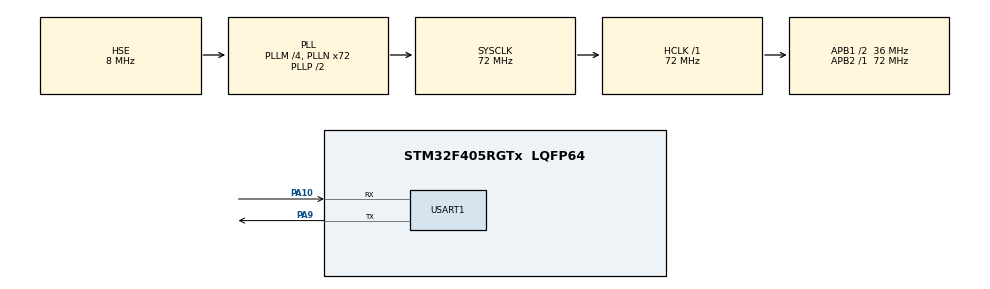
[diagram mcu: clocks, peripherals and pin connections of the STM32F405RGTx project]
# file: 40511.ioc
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Mcu.Family=STM32F4
Mcu.Name=STM32F405RGTx
Mcu.Package=LQFP64
NVIC.PriorityGroup=NVIC_PRIORITYGROUP_4
NVIC.TIM4_IRQn=true\:0\:0\:false\:false\:true
NVIC.USART1_IRQn=true\:0\:0\:false\:false\:true
PA10.Mode=Asynchronous
PA10.Signal=USART1_RX
PA9.Mode=Asynchronous
PA9.Signal=USART1_TX
PH0-OSC_IN.Mode=HSE-External-Oscillator
PH0-OSC_IN.Signal=RCC_OSC_IN
PH1-OSC_OUT.Mode=HSE-External-Oscillator
PH1-OSC_OUT.Signal=RCC_OSC_OUT
ProjectManager.HeapSize=0x2000
ProjectManager.StackSize=0x4000
ProjectManager.TargetToolchain=EWARM
RCC.48MHZClocksFreq_Value=36000000
RCC.AHBFreq_Value=72000000
RCC.APB1CLKDivider=RCC_HCLK_DIV2
RCC.APB1Freq_Value=36000000
RCC.APB1TimFreq_Value=72000000
RCC.APB2Freq_Value=72000000
RCC.APB2TimFreq_Value=72000000
RCC.CortexFreq_Value=72000000
RCC.HCLKFreq_Value=72000000
RCC.HSE_VALUE=8000000
RCC.HSI_VALUE=16000000
RCC.LSE_VALUE=32768
RCC.PLLM=4
RCC.PLLN=72
RCC.PLLSourceVirtual=RCC_PLLSOURCE_HSE
RCC.SYSCLKFreq_VALUE=72000000
RCC.SYSCLKSource=RCC_SYSCLKSOURCE_PLLCLK
RCC.VCOOutputFreq_Value=144000000
TIM4.CounterMode=TIM_COUNTERMODE_UP
TIM4.Period=50
TIM4.Prescaler=35
VP_TIM4_VS_ClockSourceINT.Mode=Internal
board=40511

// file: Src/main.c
/**
  ******************************************************************************
  * File Name          : main.c
  * Description        : Main program body
  ******************************************************************************
  *
  * COPYRIGHT(c) 2016 STMicroelectronics
  *
  * Redistribution and use in source and binary forms, with or without modification,
  * are permitted provided that the following conditions are met:
  *   1. Redistributions of source code must retain the above copyright notice,
  *      this list of conditions and the following disclaimer.
  *   2. Redistributions in binary form must reproduce the above copyright notice,
  *      this list of conditions and the following disclaimer in the documentation
  *      and/or other materials provided with the distribution.
  *   3. Neither the name of STMicroelectronics nor the names of its contributors
  *      may be used to endorse or promote products derived from this software
  *      without specific prior written permission.
  *
  * THIS SOFTWARE IS PROVIDED BY THE COPYRIGHT HOLDERS AND CONTRIBUTORS "AS IS"
  * AND ANY EXPRESS OR IMPLIED WARRANTIES, INCLUDING, BUT NOT LIMITED TO, THE
  * IMPLIED WARRANTIES OF MERCHANTABILITY AND FITNESS FOR A PARTICULAR PURPOSE ARE
  * DISCLAIMED. IN NO EVENT SHALL THE COPYRIGHT HOLDER OR CONTRIBUTORS BE LIABLE
  * FOR ANY DIRECT, INDIRECT, INCIDENTAL, SPECIAL, EXEMPLARY, OR CONSEQUENTIAL
  * DAMAGES (INCLUDING, BUT NOT LIMITED TO, PROCUREMENT OF SUBSTITUTE GOODS OR
  * SERVICES; LOSS OF USE, DATA, OR PROFITS; OR BUSINESS INTERRUPTION) HOWEVER
  * CAUSED AND ON ANY THEORY OF LIABILITY, WHETHER IN CONTRACT, STRICT LIABILITY,
  * OR TORT (INCLUDING NEGLIGENCE OR OTHERWISE) ARISING IN ANY WAY OUT OF THE USE
  * OF THIS SOFTWARE, EVEN IF ADVISED OF THE POSSIBILITY OF SUCH DAMAGE.
  *
  ******************************************************************************
  */
#include "main.h"
#include "stm32f4xx_hal.h"
#include "tim.h"
#include "usart.h"
#include "gpio.h"

/* USER CODE BEGIN Includes */
#include "mb.h"
#include "mbport.h"
#include "mbutils.h"
/* USER CODE END Includes */

/* USER CODE BEGIN PV */

/* Private variables ---------------------------------------------------------*/
#define REG_INPUT_START 0001
#define REG_INPUT_NREGS 100
#define REG_HOLDING_START 0001
#define REG_HOLDING_NREGS 100
#define REG_COILS_START     0001
#define REG_COILS_SIZE      16
#define REG_DISC_START     0001
#define REG_DISC_SIZE      16

/* ----------------------- Static variables ---------------------------------*/
static USHORT usRegInputStart = REG_INPUT_START;
static USHORT usRegInputBuf[REG_INPUT_NREGS];
static USHORT usRegHoldingStart = REG_HOLDING_START;
static USHORT usRegHoldingBuf[REG_HOLDING_NREGS];
static UCHAR ucRegCoilsBuf[REG_COILS_SIZE / 8];
static UCHAR ucRegDiscBuf[REG_DISC_SIZE / 8] =
  { 0, 0 };
/* USER CODE END PV */

void SystemClock_Config(void);
void Error_Handler(void);

/* USER CODE BEGIN PFP */

/* Private function prototypes -----------------------------------------------*/

/* USER CODE END PFP */

/* USER CODE BEGIN 0 */
//uint8_t i=10;
/* USER CODE END 0 */

int main(void)
{

  /* USER CODE BEGIN 1 */
   usRegHoldingBuf[0]=88;
   usRegHoldingBuf[2]=88;
   usRegHoldingBuf[1]=88;
   usRegHoldingBuf[3]=88;
    usRegInputBuf[1]=88;
  /* USER CODE END 1 */

  /* MCU Configuration----------------------------------------------------------*/

  /* Reset of all peripherals, Initializes the Flash interface and the Systick. */
  HAL_Init();

  /* Configure the system clock */
  SystemClock_Config();

  /* Initialize all configured peripherals */
  MX_GPIO_Init();
  MX_USART1_UART_Init();
  MX_TIM4_Init();

  /* USER CODE BEGIN 2 */
  eMBErrorCode eStatus;
  eStatus=eMBInit(MB_RTU, 0x01, 0, 9600, MB_PAR_NONE);
  eStatus=eMBEnable();
  /* USER CODE END 2 */

  /* Infinite loop */
  while (1)
  {

  /* USER CODE BEGIN 3 */
   //HAL_UART_Transmit(&huart1,&i,1,10);
   //HAL_Delay(100);
    ( void )eMBPoll();
  }
  /* USER CODE END 3 */

}

/** System Clock Configuration
*/
void SystemClock_Config(void)
{

  RCC_OscInitTypeDef RCC_OscInitStruct;
  RCC_ClkInitTypeDef RCC_ClkInitStruct;

    /**Configure the main internal regulator output voltage
    */
  __HAL_RCC_PWR_CLK_ENABLE();

  __HAL_PWR_VOLTAGESCALING_CONFIG(PWR_REGULATOR_VOLTAGE_SCALE1);

    /**Initializes the CPU, AHB and APB busses clocks
    */
  RCC_OscInitStruct.OscillatorType = RCC_OSCILLATORTYPE_HSE;
  RCC_OscInitStruct.HSEState = RCC_HSE_ON;
  RCC_OscInitStruct.PLL.PLLState = RCC_PLL_ON;
  RCC_OscInitStruct.PLL.PLLSource = RCC_PLLSOURCE_HSE;
  RCC_OscInitStruct.PLL.PLLM = 4;
  RCC_OscInitStruct.PLL.PLLN = 72;
  RCC_OscInitStruct.PLL.PLLP = RCC_PLLP_DIV2;
  RCC_OscInitStruct.PLL.PLLQ = 4;
  if (HAL_RCC_OscConfig(&RCC_OscInitStruct) != HAL_OK)
  {
    Error_Handler();
  }

    /**Initializes the CPU, AHB and APB busses clocks
    */
  RCC_ClkInitStruct.ClockType = RCC_CLOCKTYPE_HCLK|RCC_CLOCKTYPE_SYSCLK
                              |RCC_CLOCKTYPE_PCLK1|RCC_CLOCKTYPE_PCLK2;
  RCC_ClkInitStruct.SYSCLKSource = RCC_SYSCLKSOURCE_PLLCLK;
  RCC_ClkInitStruct.AHBCLKDivider = RCC_SYSCLK_DIV1;
  RCC_ClkInitStruct.APB1CLKDivider = RCC_HCLK_DIV2;
  RCC_ClkInitStruct.APB2CLKDivider = RCC_HCLK_DIV1;

  if (HAL_RCC_ClockConfig(&RCC_ClkInitStruct, FLASH_LATENCY_2) != HAL_OK)
  {
    Error_Handler();
  }

    /**Configure the Systick interrupt time
    */
  HAL_SYSTICK_Config(HAL_RCC_GetHCLKFreq()/1000);

    /**Configure the Systick
    */
  HAL_SYSTICK_CLKSourceConfig(SYSTICK_CLKSOURCE_HCLK);

  /* SysTick_IRQn interrupt configuration */
  HAL_NVIC_SetPriority(SysTick_IRQn, 0, 0);
}

/* USER CODE BEGIN 4 */
eMBErrorCode eMBRegInputCB(UCHAR * pucRegBuffer, USHORT usAddress, USHORT usNRegs)
{
  eMBErrorCode eStatus = MB_ENOERR;
  int iRegIndex;
  //printf("%d\n", usAddress);
  if ((usAddress >= REG_INPUT_START)
      && (usAddress + usNRegs <= REG_INPUT_START + REG_INPUT_NREGS))
    {
      iRegIndex = (int) (usAddress - usRegInputStart);
      while (usNRegs > 0)
        {
          *pucRegBuffer++ = (unsigned char) (usRegInputBuf[iRegIndex] >> 8);
          *pucRegBuffer++ = (unsigned char) (usRegInputBuf[iRegIndex] & 0xFF);
          iRegIndex++;
          usNRegs--;
        }
    }
  else
    {
      eStatus = MB_ENOREG;
    }

  return eStatus;
}

eMBErrorCode eMBRegHoldingCB(UCHAR * pucRegBuffer, USHORT usAddress, USHORT usNRegs, eMBRegisterMode eMode)
{
  eMBErrorCode eStatus;
  int iRegIndex;
  if ((usAddress >= REG_HOLDING_START)
      && (usAddress + usNRegs <= REG_HOLDING_START + REG_HOLDING_NREGS))
    {
      iRegIndex = (int) (usAddress - usRegHoldingStart);
      switch (eMode)
        {
      case MB_REG_READ:
        while (usNRegs > 0)
          {
            *pucRegBuffer++ = (UCHAR) (usRegHoldingBuf[iRegIndex] >> 8);
            *pucRegBuffer++ = (UCHAR) (usRegHoldingBuf[iRegIndex] & 0xFF);
            iRegIndex++;
            usNRegs--;
          }
        break;
      case MB_REG_WRITE:
        while (usNRegs > 0)
          {
            usRegHoldingBuf[iRegIndex] = (USHORT) (*pucRegBuffer++ << 8);
            usRegHoldingBuf[iRegIndex] |= (USHORT) (*pucRegBuffer++);
            iRegIndex++;
            usNRegs--;
          }
        }
    }
  else
    {
      eStatus = MB_ENOREG;
    }
  return eStatus;
}

eMBErrorCode eMBRegCoilsCB(UCHAR * pucRegBuffer, USHORT usAddress, USHORT usNCoils, eMBRegisterMode eMode)
{
  eMBErrorCode eStatus = MB_ENOERR;
  int iNCoils = (int) usNCoils;
  unsigned short usBitOffset;

  /* Check if we have registers mapped at this block. */
  if ((usAddress >= REG_COILS_START)
      && (usAddress + usNCoils <= REG_COILS_START + REG_COILS_SIZE))
    {
      usBitOffset = (unsigned short) (usAddress - REG_COILS_START);
      switch (eMode)
        {
      /* Read current values and pass to protocol stack. */
      case MB_REG_READ:
        while (iNCoils > 0)
          {
            *pucRegBuffer++ = xMBUtilGetBits(ucRegCoilsBuf, usBitOffset,
                (unsigned char) (iNCoils > 8 ? 8 : iNCoils));
            iNCoils -= 8;
            usBitOffset += 8;
          }
        break;

        /* Update current register values. */
      case MB_REG_WRITE:
        while (iNCoils > 0)
          {
            xMBUtilSetBits(ucRegCoilsBuf, usBitOffset,
                (unsigned char) (iNCoils > 8 ? 8 : iNCoils), *pucRegBuffer++);
            iNCoils -= 8;
            usBitOffset += 8;
          }
        break;
        }

    }
  else
    {
      eStatus = MB_ENOREG;
    }
  return eStatus;
}

eMBErrorCode eMBRegDiscreteCB(UCHAR * pucRegBuffer, USHORT usAddress, USHORT usNDiscrete)
{
  eMBErrorCode eStatus = MB_ENOERR;
  short iNDiscrete = (short) usNDiscrete;
  unsigned short usBitOffset;

  /* Check if we have registers mapped at this block. */
  if ((usAddress >= REG_DISC_START)
      && (usAddress + usNDiscrete <= REG_DISC_START + REG_DISC_SIZE))
    {
      usBitOffset = (unsigned short) (usAddress - REG_DISC_START);
      while (iNDiscrete > 0)
        {
          *pucRegBuffer++ = xMBUtilGetBits(ucRegDiscBuf, usBitOffset,
              (unsigned char) (iNDiscrete > 8 ? 8 : iNDiscrete));
          iNDiscrete -= 8;
          usBitOffset += 8;
        }
    }
  else
    {
      eStatus = MB_ENOREG;
    }
  return eStatus;
}
/* USER CODE END 4 */

void Error_Handler(void)
{
  while(1)
  {
  }
}

/************************ (C) COPYRIGHT STMicroelectronics *****END OF FILE****/
